AUTOSAR XML (schema 4-2-2)
package /STELLANTIS/EPT/ASWCs
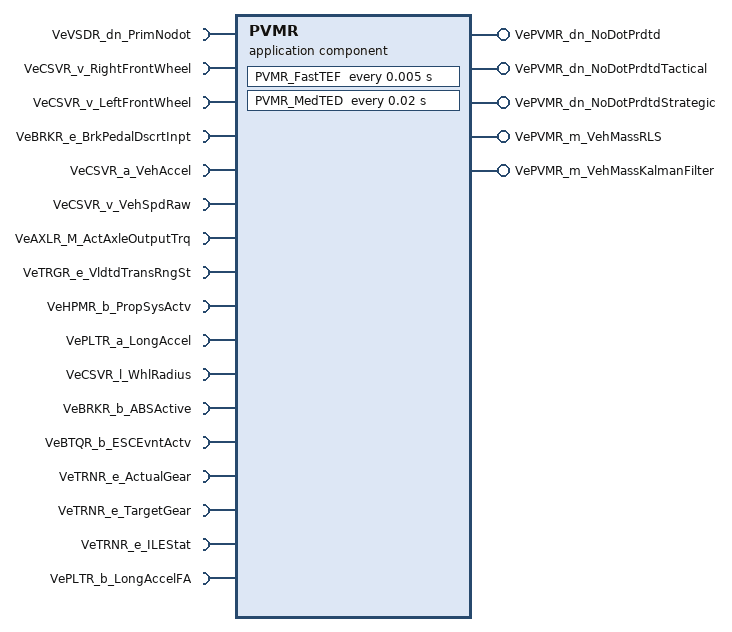
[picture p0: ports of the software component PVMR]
  application sw component type PVMR
    17 x require port:
      VeVSDR_dn_PrimNodot: nonqueued-receiver-com-spec{data-element=Value, init-value=0}, required-interface=VeVSDR_dn_PrimNodot
      VeCSVR_v_RightFrontWheel: nonqueued-receiver-com-spec{data-element=Value, init-value=0}, required-interface=VeCSVR_v_RightFrontWheel
      VeCSVR_v_LeftFrontWheel: nonqueued-receiver-com-spec{data-element=Value, init-value=0}, required-interface=VeCSVR_v_LeftFrontWheel
      VeBRKR_e_BrkPedalDscrtInpt: nonqueued-receiver-com-spec{data-element=Value, init-value=CeBRKR_e_BrkNotApplied}, required-interface=VeBRKR_e_BrkPedalDscrtInpt
      VeCSVR_a_VehAccel: nonqueued-receiver-com-spec{data-element=Value, init-value=0}, required-interface=VeCSVR_a_VehAccel
      VeCSVR_v_VehSpdRaw: nonqueued-receiver-com-spec{data-element=Value, init-value=0}, required-interface=VeCSVR_v_VehSpdRaw
      VeAXLR_M_ActAxleOutputTrq: nonqueued-receiver-com-spec{data-element=Value, init-value=0}, required-interface=VeAXLR_M_ActAxleOutputTrq
      VeTRGR_e_VldtdTransRngSt: nonqueued-receiver-com-spec{data-element=Value, init-value=CeTRGR_e_NoSelectionAvailable}, required-interface=VeTRGR_e_VldtdTransRngSt
      VeHPMR_b_PropSysActv: nonqueued-receiver-com-spec{data-element=Value, init-value=0}, required-interface=VeHPMR_b_PropSysActv
      VePLTR_a_LongAccel: nonqueued-receiver-com-spec{data-element=Value, init-value=0}, required-interface=VePLTR_a_LongAccel
      VeCSVR_l_WhlRadius: nonqueued-receiver-com-spec{data-element=Value, init-value=0}, required-interface=VeCSVR_l_WhlRadius
      VeBRKR_b_ABSActive: nonqueued-receiver-com-spec{data-element=Value, init-value=0}, required-interface=VeBRKR_b_ABSActive
      VeBTQR_b_ESCEvntActv: nonqueued-receiver-com-spec{data-element=Value, init-value=0}, required-interface=VeBTQR_b_ESCEvntActv
      VeTRNR_e_ActualGear: nonqueued-receiver-com-spec{data-element=Value, init-value=CeTRNR_e_Neutral}, required-interface=VeTRNR_e_ActualGear
      VeTRNR_e_TargetGear: nonqueued-receiver-com-spec{data-element=Value, init-value=CeTRNR_e_Neutral}, required-interface=VeTRNR_e_TargetGear
      VeTRNR_e_ILEStat: nonqueued-receiver-com-spec{data-element=Value, init-value=CeHCCR_e_ClInvalid}, required-interface=VeTRNR_e_ILEStat
      VePLTR_b_LongAccelFA: nonqueued-receiver-com-spec{data-element=Value, init-value=0}, required-interface=VePLTR_b_LongAccelFA
    5 x provide port, all with nonqueued-sender-com-spec{data-element=Value, init-value=0}:
      VePVMR_dn_NoDotPrdtd: provided-interface=VePVMR_dn_NoDotPrdtd
      VePVMR_dn_NoDotPrdtdTactical: provided-interface=VePVMR_dn_NoDotPrdtdTactical
      VePVMR_dn_NoDotPrdtdStrategic: provided-interface=VePVMR_dn_NoDotPrdtdStrategic
      VePVMR_m_VehMassRLS: provided-interface=VePVMR_m_VehMassRLS
      VePVMR_m_VehMassKalmanFilter: provided-interface=VePVMR_m_VehMassKalmanFilter
    behavior IB_PVMR: data-type-mapping=msADTtoIDTMapping, handle-termination-and-restart=NO-SUPPORT
      timing event Event_FastTEF: start-on-event=PVMR_FastTEF, period=0.005
      timing event Event_MedTED: start-on-event=PVMR_MedTED, period=0.02
      init event Event_PVMR_ac_Init: start-on-event=PVMR_ac_Init
      init event Event_PwrOn: start-on-event=PVMR_PwrOn
      4 x runnable:
        PVMR_ac_Init
        PVMR_PwrOn
          data-send-points:
            5 x access:
              OUT_VePVMR_dn_NoDotPrdtd_Value: accessed-variable=VePVMR_dn_NoDotPrdtd.Value
              OUT_VePVMR_dn_NoDotPrdtdTactical_Value: accessed-variable=VePVMR_dn_NoDotPrdtdTactical.Value
              OUT_VePVMR_dn_NoDotPrdtdStrategic_Value: accessed-variable=VePVMR_dn_NoDotPrdtdStrategic.Value
              OUT_VePVMR_m_VehMassRLS_Value: accessed-variable=VePVMR_m_VehMassRLS.Value
              OUT_VePVMR_m_VehMassKalmanFilter_Value: accessed-variable=VePVMR_m_VehMassKalmanFilter.Value
        PVMR_FastTEF
          data-receive-point-by-arguments:
            access IN_VeVSDR_dn_PrimNodot_Value: accessed-variable=VeVSDR_dn_PrimNodot.Value
          data-send-points:
            access OUT_VePVMR_dn_NoDotPrdtd_Value: accessed-variable=VePVMR_dn_NoDotPrdtd.Value
            access OUT_VePVMR_dn_NoDotPrdtdTactical_Value: accessed-variable=VePVMR_dn_NoDotPrdtdTactical.Value
            access OUT_VePVMR_dn_NoDotPrdtdStrategic_Value: accessed-variable=VePVMR_dn_NoDotPrdtdStrategic.Value
        PVMR_MedTED
          data-receive-point-by-arguments:
            16 x access:
              IN_VeAXLR_M_ActAxleOutputTrq_Value: accessed-variable=VeAXLR_M_ActAxleOutputTrq.Value
              IN_VeBRKR_b_ABSActive_Value: accessed-variable=VeBRKR_b_ABSActive.Value
              IN_VeBRKR_e_BrkPedalDscrtInpt_Value: accessed-variable=VeBRKR_e_BrkPedalDscrtInpt.Value
              IN_VeBTQR_b_ESCEvntActv_Value: accessed-variable=VeBTQR_b_ESCEvntActv.Value
              IN_VeCSVR_a_VehAccel_Value: accessed-variable=VeCSVR_a_VehAccel.Value
              IN_VeCSVR_l_WhlRadius_Value: accessed-variable=VeCSVR_l_WhlRadius.Value
              IN_VeCSVR_v_LeftFrontWheel_Value: accessed-variable=VeCSVR_v_LeftFrontWheel.Value
              IN_VeCSVR_v_RightFrontWheel_Value: accessed-variable=VeCSVR_v_RightFrontWheel.Value
              IN_VeCSVR_v_VehSpdRaw_Value: accessed-variable=VeCSVR_v_VehSpdRaw.Value
              IN_VeHPMR_b_PropSysActv_Value: accessed-variable=VeHPMR_b_PropSysActv.Value
              IN_VePLTR_a_LongAccel_Value: accessed-variable=VePLTR_a_LongAccel.Value
              IN_VePLTR_b_LongAccelFA_Value: accessed-variable=VePLTR_b_LongAccelFA.Value
              IN_VeTRGR_e_VldtdTransRngSt_Value: accessed-variable=VeTRGR_e_VldtdTransRngSt.Value
              IN_VeTRNR_e_ActualGear_Value: accessed-variable=VeTRNR_e_ActualGear.Value
              IN_VeTRNR_e_ILEStat_Value: accessed-variable=VeTRNR_e_ILEStat.Value
              IN_VeTRNR_e_TargetGear_Value: accessed-variable=VeTRNR_e_TargetGear.Value
          data-send-points:
            access OUT_VePVMR_m_VehMassRLS_Value: accessed-variable=VePVMR_m_VehMassRLS.Value
            access OUT_VePVMR_m_VehMassKalmanFilter_Value: accessed-variable=VePVMR_m_VehMassKalmanFilter.Value
